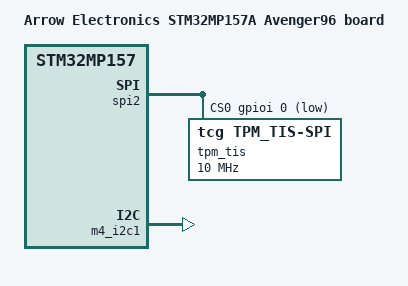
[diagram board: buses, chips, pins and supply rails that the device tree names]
// SPDX-License-Identifier: (GPL-2.0+ OR BSD-3-Clause)
/*
 * Copyright (C) Arrow Electronics 2020 - All Rights Reserved
 * Author: Botond Kardos <botond.kardos@arroweurope.com> for Arrow Electronics
 */
/dts-v1/;

#include "stm32mp157a-av96.dtsi"

/ {
	model = "Arrow Electronics STM32MP157A Avenger96 board";
	compatible = "st,stm32mp157a-av96", "st,stm32mp157c-ed1", "st,stm32mp157";
};

/* Tresor board */
&spi2 {
	pinctrl-names = "default", "sleep";
	pinctrl-0 = <&spi2_pins_a>;
	pinctrl-1 = <&spi2_sleep_pins_a>;
	status = "okay";
	cs-gpios = <&gpioi 0 GPIO_ACTIVE_LOW>;

	tpm_tis@0 {
		compatible = "tcg,tpm_tis-spi";
		reg = <0>;
		spi-max-frequency = <10000000>;
	};
};

&m4_i2c1 {
	pinctrl-names = "default";
	pinctrl-0 = <&i2c1_pins_a>;
	status = "okay";
};
